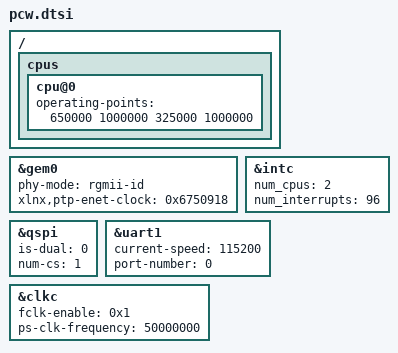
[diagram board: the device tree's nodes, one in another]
/*
 * CAUTION: This file is automatically generated by Xilinx.
 * Version: HSI 2016.2
 * Today is: Wed Aug 17 14:26:41 2016
*/


/ {
	cpus {
		cpu@0 {
			operating-points = <650000 1000000 325000 1000000>;
		};
	};
};
&gem0 {
	phy-mode = "rgmii-id";
	status = "okay";
	xlnx,ptp-enet-clock = <0x6750918>;
};
&intc {
	num_cpus = <2>;
	num_interrupts = <96>;
};
&qspi {
	is-dual = <0>;
	num-cs = <1>;
	status = "okay";
};
&uart1 {
	current-speed = <115200>;
	device_type = "serial";
	port-number = <0>;
	status = "okay";
};
&clkc {
	fclk-enable = <0x1>;
	ps-clk-frequency = <50000000>;
};
